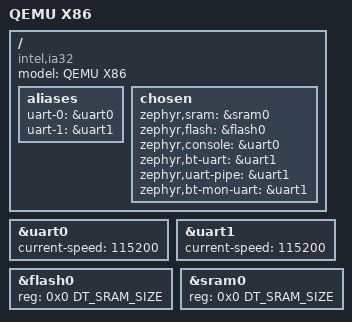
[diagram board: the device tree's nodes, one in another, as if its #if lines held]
/dts-v1/;

#include <mem.h>

#define DT_FLASH_SIZE		DT_SIZE_K(4092)

#if XIP
	#define DT_SRAM_SIZE		DT_SIZE_K(4096)
#else
	#define DT_SRAM_SIZE		DT_SIZE_K(8188)
#endif

#include <ia32.dtsi>

/ {
	model = "QEMU X86";
	compatible = "intel,ia32";

	aliases {
		uart-0 = &uart0;
		uart-1 = &uart1;
	};

	chosen {
		zephyr,sram = &sram0;
		zephyr,flash = &flash0;
		zephyr,console = &uart0;
		zephyr,bt-uart = &uart1;
		zephyr,uart-pipe = &uart1;
		zephyr,bt-mon-uart = &uart1;
	};
};

&uart0 {
	status = "ok";
	current-speed = <115200>;
};

&uart1 {
	status = "ok";
	current-speed = <115200>;
};

&flash0 {
	reg = <0x0 DT_SRAM_SIZE>;
};

&sram0 {
	reg = <0x0 DT_SRAM_SIZE>;
};
